# N32H482 register map
Vendor: Nationstech Ltd.; File version: 1.0
Registers are 32-bit, read-write, reset 0x0 unless marked. A register's access mark holds for its fields unless they carry their own. Offsets are from the block's base; [hi:lo] are bit positions; 'fields as' and 'values as' point back to an identical list.

## DAC78
Base 0x4002AC00
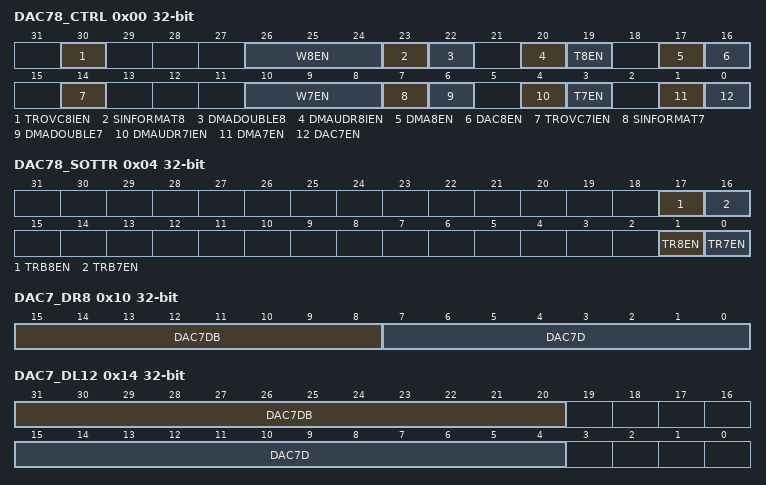
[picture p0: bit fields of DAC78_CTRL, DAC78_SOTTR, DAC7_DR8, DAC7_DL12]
0x00 DAC78_CTRL
  [30] TROVC8IEN, [26:24] W8EN, [23] SINFORMAT8, [22] DMADOUBLE8, [20] DMAUDR8IEN, [19] T8EN, [17] DMA8EN, [16] DAC8EN, [14] TROVC7IEN, [10:8] W7EN, [7] SINFORMAT7, [6] DMADOUBLE7, [4] DMAUDR7IEN, [3] T7EN, [1] DMA7EN, [0] DAC7EN
0x04 DAC78_SOTTR
  [17] TRB8EN, [16] TRB7EN, [1] TR8EN, [0] TR7EN
0x08 DAC7_DATO
  [11:0] DAC7DO
0x0C DAC8_DATO
  [11:0] DAC8DO
0x10 DAC7_DR8
  [15:8] DAC7DB, [7:0] DAC7D
0x14 DAC7_DL12
  [31:20] DAC7DB, [15:4] DAC7D
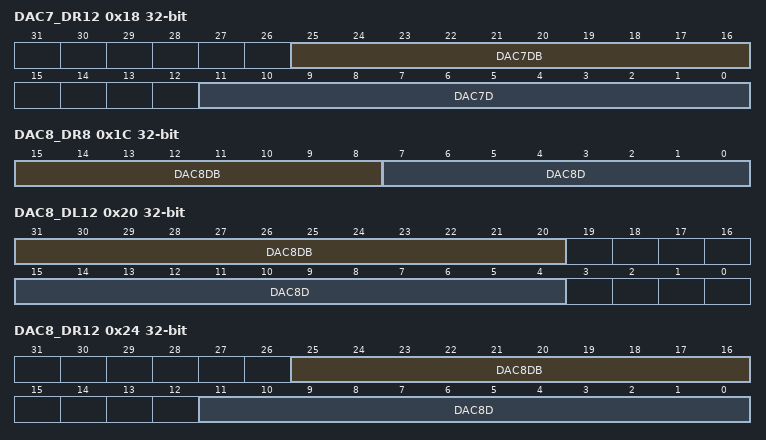
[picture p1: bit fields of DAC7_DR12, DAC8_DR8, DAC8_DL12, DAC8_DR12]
0x18 DAC7_DR12
  [25:16] DAC7DB, [11:0] DAC7D
0x1C DAC8_DR8
  [15:8] DAC8DB, [7:0] DAC8D
0x20 DAC8_DL12
  [31:20] DAC8DB, [15:4] DAC8D
0x24 DAC8_DR12
  [25:16] DAC8DB, [11:0] DAC8D
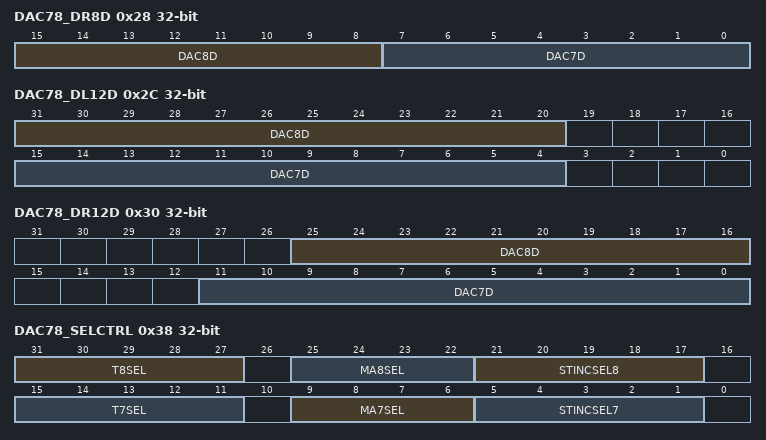
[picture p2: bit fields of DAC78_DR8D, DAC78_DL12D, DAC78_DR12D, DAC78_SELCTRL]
0x28 DAC78_DR8D
  [15:8] DAC8D, [7:0] DAC7D
0x2C DAC78_DL12D
  [31:20] DAC8D, [15:4] DAC7D
0x30 DAC78_DR12D
  [25:16] DAC8D, [11:0] DAC7D
0x38 DAC78_SELCTRL
  [31:27] T8SEL, [25:22] MA8SEL, [21:17] STINCSEL8, [15:11] T7SEL, [9:6] MA7SEL, [5:1] STINCSEL7
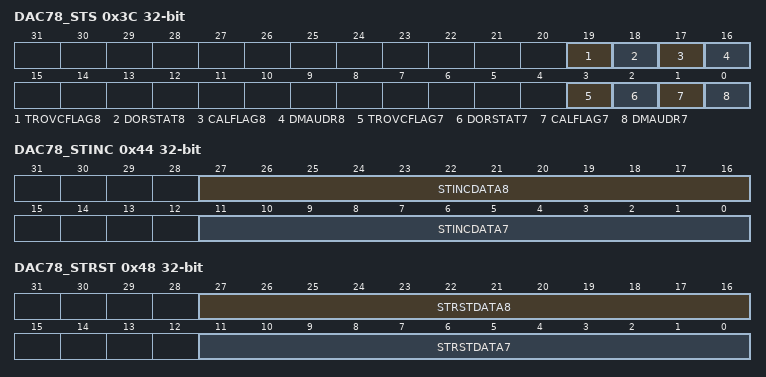
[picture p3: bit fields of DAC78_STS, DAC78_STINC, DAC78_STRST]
0x3C DAC78_STS
  [19] TROVCFLAG8, [18] DORSTAT8, [17] CALFLAG8, [16] DMAUDR8, [3] TROVCFLAG7, [2] DORSTAT7, [1] CALFLAG7, [0] DMAUDR7
0x40 DAC78_GCTRL reset 0x770000
  [20:16] PCS
0x44 DAC78_STINC
  [27:16] STINCDATA8, [11:0] STINCDATA7
0x48 DAC78_STRST
  [27:16] STRSTDATA8, [11:0] STRSTDATA7

## FEMC — Flexible external memory controller
Base 0xA0002000
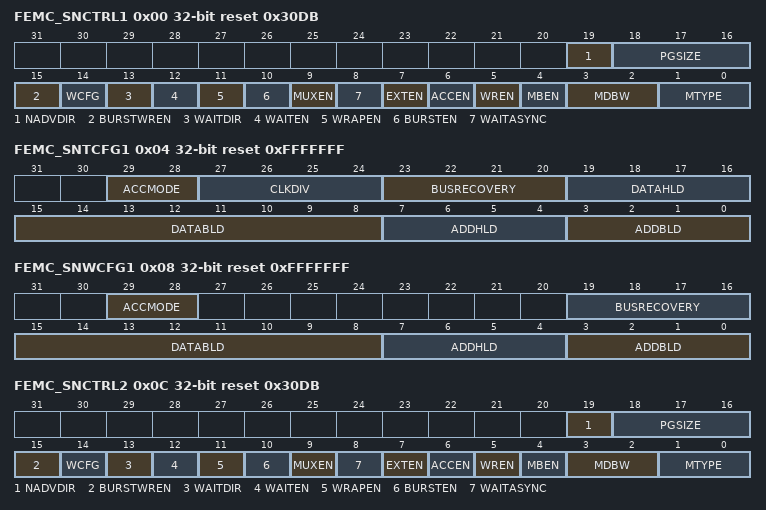
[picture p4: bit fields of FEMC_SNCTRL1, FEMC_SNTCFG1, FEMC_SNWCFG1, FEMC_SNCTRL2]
0x00 FEMC_SNCTRL1 reset 0x30DB
  [19] NADVDIR, [18:16] PGSIZE, [15] BURSTWREN, [14] WCFG, [13] WAITDIR, [12] WAITEN, [11] WRAPEN, [10] BURSTEN, [9] MUXEN, [8] WAITASYNC, [7] EXTEN, [6] ACCEN, [5] WREN, [4] MBEN, [3:2] MDBW, [1:0] MTYPE
0x04 FEMC_SNTCFG1 reset 0xFFFFFFF
  [29:28] ACCMODE, [27:24] CLKDIV, [23:20] BUSRECOVERY, [19:16] DATAHLD, [15:8] DATABLD, [7:4] ADDHLD, [3:0] ADDBLD
0x08 FEMC_SNWCFG1 reset 0xFFFFFFF
  [29:28] ACCMODE, [19:16] BUSRECOVERY, [15:8] DATABLD, [7:4] ADDHLD, [3:0] ADDBLD
0x0C FEMC_SNCTRL2 reset 0x30DB
  fields as FEMC_SNCTRL1
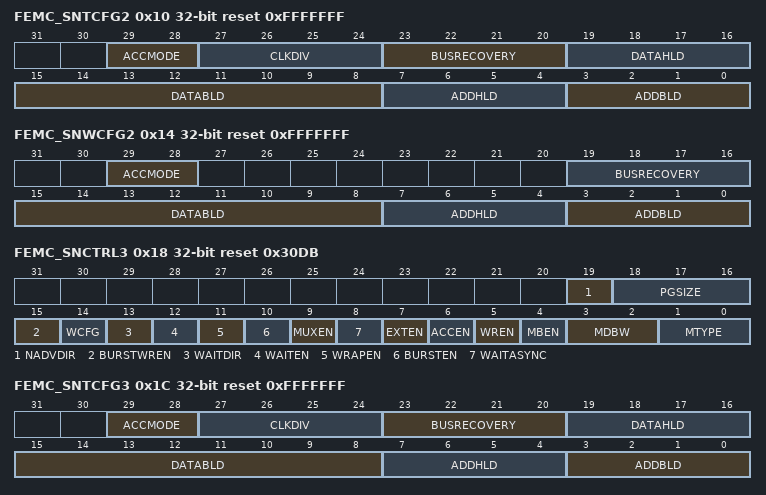
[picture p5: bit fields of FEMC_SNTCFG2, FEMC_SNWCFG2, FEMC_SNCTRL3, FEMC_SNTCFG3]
0x10 FEMC_SNTCFG2 reset 0xFFFFFFF
  fields as FEMC_SNTCFG1
0x14 FEMC_SNWCFG2 reset 0xFFFFFFF
  fields as FEMC_SNWCFG1
0x18 FEMC_SNCTRL3 reset 0x30DB
  fields as FEMC_SNCTRL1
0x1C FEMC_SNTCFG3 reset 0xFFFFFFF
  fields as FEMC_SNTCFG1
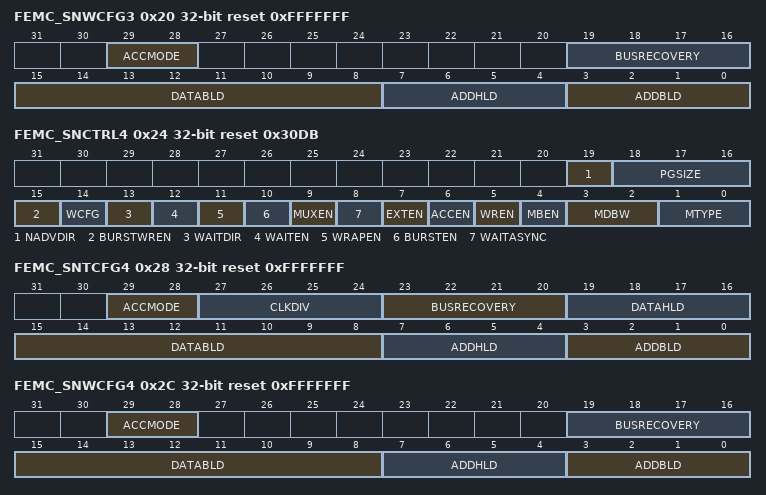
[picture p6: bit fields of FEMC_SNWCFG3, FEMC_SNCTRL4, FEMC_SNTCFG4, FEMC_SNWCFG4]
0x20 FEMC_SNWCFG3 reset 0xFFFFFFF
  fields as FEMC_SNWCFG1
0x24 FEMC_SNCTRL4 reset 0x30DB
  fields as FEMC_SNCTRL1
0x28 FEMC_SNTCFG4 reset 0xFFFFFFF
  fields as FEMC_SNTCFG1
0x2C FEMC_SNWCFG4 reset 0xFFFFFFF
  fields as FEMC_SNWCFG1
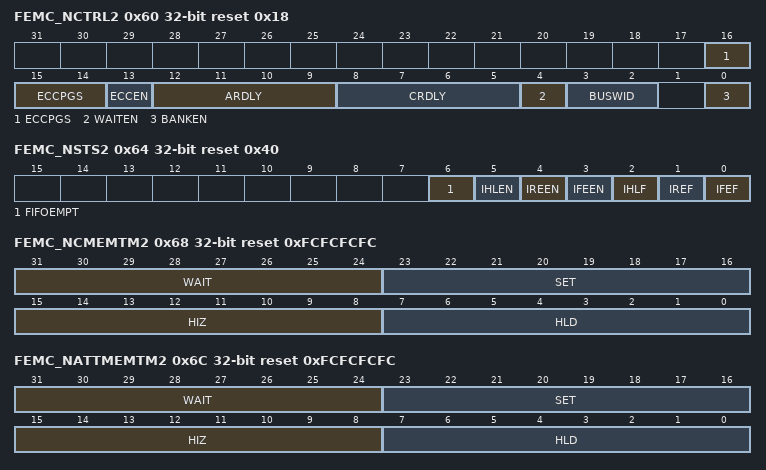
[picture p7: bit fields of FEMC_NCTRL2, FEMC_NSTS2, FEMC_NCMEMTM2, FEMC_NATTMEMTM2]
0x60 FEMC_NCTRL2 reset 0x18 (reset mask 0xFFE7E)
  [16:14] ECCPGS, [13] ECCEN, [12:9] ARDLY, [8:5] CRDLY, [4] WAITEN, [3:2] BUSWID, [0] BANKEN
0x64 FEMC_NSTS2 reset 0x40
  [6] FIFOEMPT, [5] IHLEN, [4] IREEN, [3] IFEEN, [2] IHLF, [1] IREF, [0] IFEF
0x68 FEMC_NCMEMTM2 reset 0xFCFCFCFC
  [31:24] WAIT, [23:16] SET, [15:8] HIZ, [7:0] HLD
0x6C FEMC_NATTMEMTM2 reset 0xFCFCFCFC
  [31:24] WAIT, [23:16] SET, [15:8] HIZ, [7:0] HLD
0x74 FEMC_ECC2 reset 0xFCFCFCFC
  [31:0] ECC
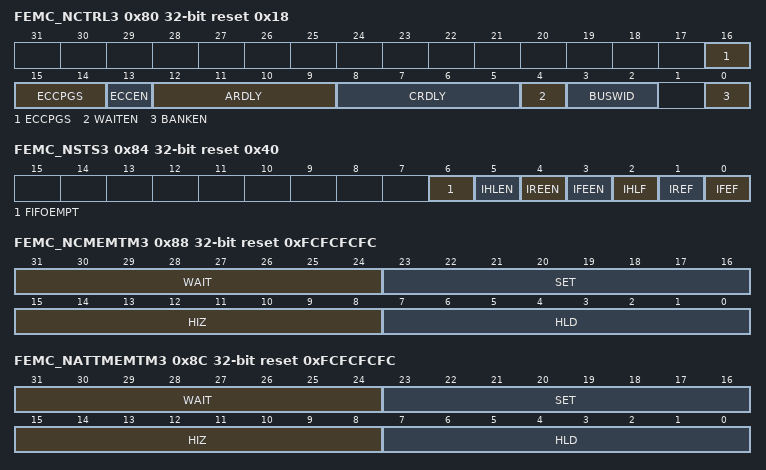
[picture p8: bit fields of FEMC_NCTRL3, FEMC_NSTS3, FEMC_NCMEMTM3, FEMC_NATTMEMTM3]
0x80 FEMC_NCTRL3 reset 0x18 (reset mask 0xFFE7E)
  fields as FEMC_NCTRL2
0x84 FEMC_NSTS3 reset 0x40
  fields as FEMC_NSTS2
0x88 FEMC_NCMEMTM3 reset 0xFCFCFCFC
  [31:24] WAIT, [23:16] SET, [15:8] HIZ, [7:0] HLD
0x8C FEMC_NATTMEMTM3 reset 0xFCFCFCFC
  [31:24] WAIT, [23:16] SET, [15:8] HIZ, [7:0] HLD
0x94 FEMC_ECC3 reset 0xFCFCFCFC
  [31:0] ECC

## FMAC — Filter math accelerator
Base 0x40021C00
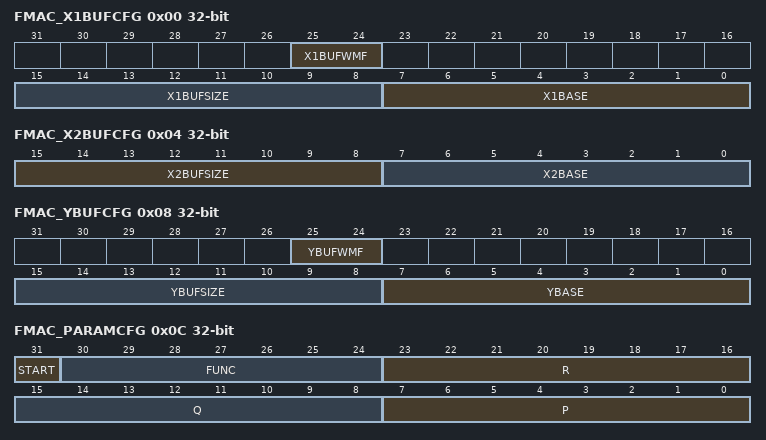
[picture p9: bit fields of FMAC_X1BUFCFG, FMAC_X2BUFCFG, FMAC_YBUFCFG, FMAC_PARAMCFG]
0x00 FMAC_X1BUFCFG
  [25:24] X1BUFWMF, [15:8] X1BUFSIZE, [7:0] X1BASE
0x04 FMAC_X2BUFCFG
  [15:8] X2BUFSIZE, [7:0] X2BASE
0x08 FMAC_YBUFCFG
  [25:24] YBUFWMF, [15:8] YBUFSIZE, [7:0] YBASE
0x0C FMAC_PARAMCFG
  [31] START, [30:24] FUNC, [23:16] R, [15:8] Q, [7:0] P
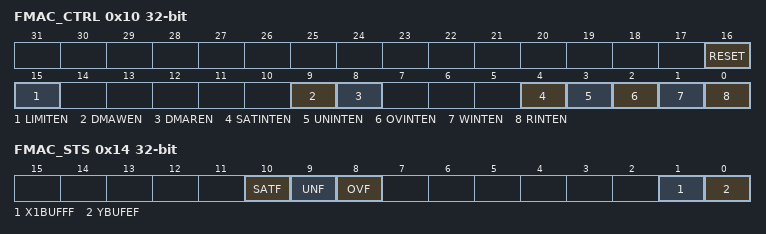
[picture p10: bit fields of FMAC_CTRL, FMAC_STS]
0x10 FMAC_CTRL
  [16] RESET, [15] LIMITEN, [9] DMAWEN, [8] DMAREN, [4] SATINTEN, [3] UNINTEN, [2] OVINTEN, [1] WINTEN, [0] RINTEN
0x14 FMAC_STS
  [10] SATF, [9] UNF, [8] OVF, [1] X1BUFFF, [0] YBUFEF
0x18 FMAC_WDAT
  [15:0] WDAT
0x1C FMAC_RDAT
  [15:0] RDAT
